# CM_CORE_AON__VPE register map
Vendor: Texas Instruments
Peripheral module from a debugger description file (folder TDA2Px).
Registers are 32-bit, access per field, reset 0x3 unless marked. A register's access mark holds for its fields unless they carry their own. Offsets are as the file gives them; lines under a group give offsets from that group; [hi:lo] are bit positions; {n}, {i} and the like mark numbered series; 'fields as' and 'values as' point back to an identical list; <NAME> marks a mode.

## CM_CORE_AON__VPE
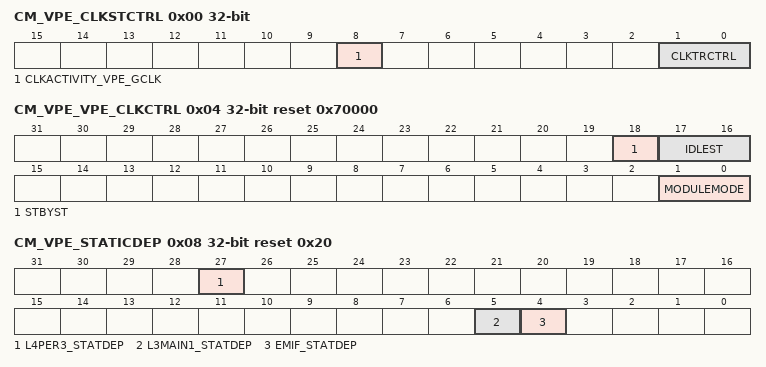
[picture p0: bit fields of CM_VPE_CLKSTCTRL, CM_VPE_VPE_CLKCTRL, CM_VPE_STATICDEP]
0x00 CM_VPE_CLKSTCTRL — This register enables the VPE domain power state transition. It controls the HW supervised domain power state transition between ON-ACTIVE and ON-INACTIVE states. It also hold one status bit per clock input of the domain.
  [8] CLKACTIVITY_VPE_GCLK ro — This field indicates the state of the VPE_GCLK clock in the domain. [warm reset insensitive]
    0=INACT (Corresponding clock is definitely gated); 1=ACT (Corresponding clock is running or gating/ungating transition is on-going)
  [1:0] CLKTRCTRL rw — Controls the clock state transition of the DSP clock domain.
    0=NO_SLEEP (NO_SLEEP: Sleep transition cannot be initiated. Wakeup transition may however occur.); 1=SW_SLEEP (SW_SLEEP: Start a software forced sleep transition on the domain.); 2=SW_WKUP (SW_WKUP: Start a software forced wake-up transition on the domain.); 3=HW_AUTO (HW_AUTO: Automatic transition is enabled. Sleep and wakeup transition are based upon hardware conditions.)
0x04 CM_VPE_VPE_CLKCTRL reset 0x70000 — This register manages the VPE clocks.
  [18] STBYST ro — Module standby status. [warm reset insensitive]
    0=FUNC (Module is functional (not in standby)); 1=STANDBY (Module is in standby)
  [17:16] IDLEST ro — Module idle status. [warm reset insensitive]
    0=FUNC (Module is fully functional, including OCP); 1=TRANS (Module is performing transition: wakeup, or sleep, or sleep abortion); 2=IDLE (Module is in Idle mode (only OCP part). It is functional if using separate functional clock); 3=DISABLE (Module is disabled and cannot be accessed)
  [1:0] MODULEMODE rw — Control the way mandatory clocks are managed.
    0=DISABLED (Module is disabled by SW. Any OCP access to module results in an error, except if resulting from a module wakeup (asynchronous wakeup).); 1=AUTO (Module is managed automatically by HW according to clock domain transition. A clock domain sleep transition put module into idle. A wakeup domain transition put it back into function. If CLKTRCTRL=3, any OCP access to module is always granted. Module clocks may be gated according to the clock domain state.)
0x08 CM_VPE_STATICDEP reset 0x20 — This register controls the static domain depedencies from VPE domain towards 'target' domains. It is relevant only for domain having system initiator(s).
  [27] L4PER3_STATDEP rw — Static dependency towards L4PER3 clock domain
    0=DISABLED (Dependency is disabled); 1=ENABLED (Dependency is enabled)
  [5] L3MAIN1_STATDEP ro — Static dependency towards L3MAIN1 clock domain
    1=ENABLED (Dependency is enabled)
  [4] EMIF_STATDEP rw — Static dependency towards EMIF clock domain
    values as L4PER3_STATDEP
